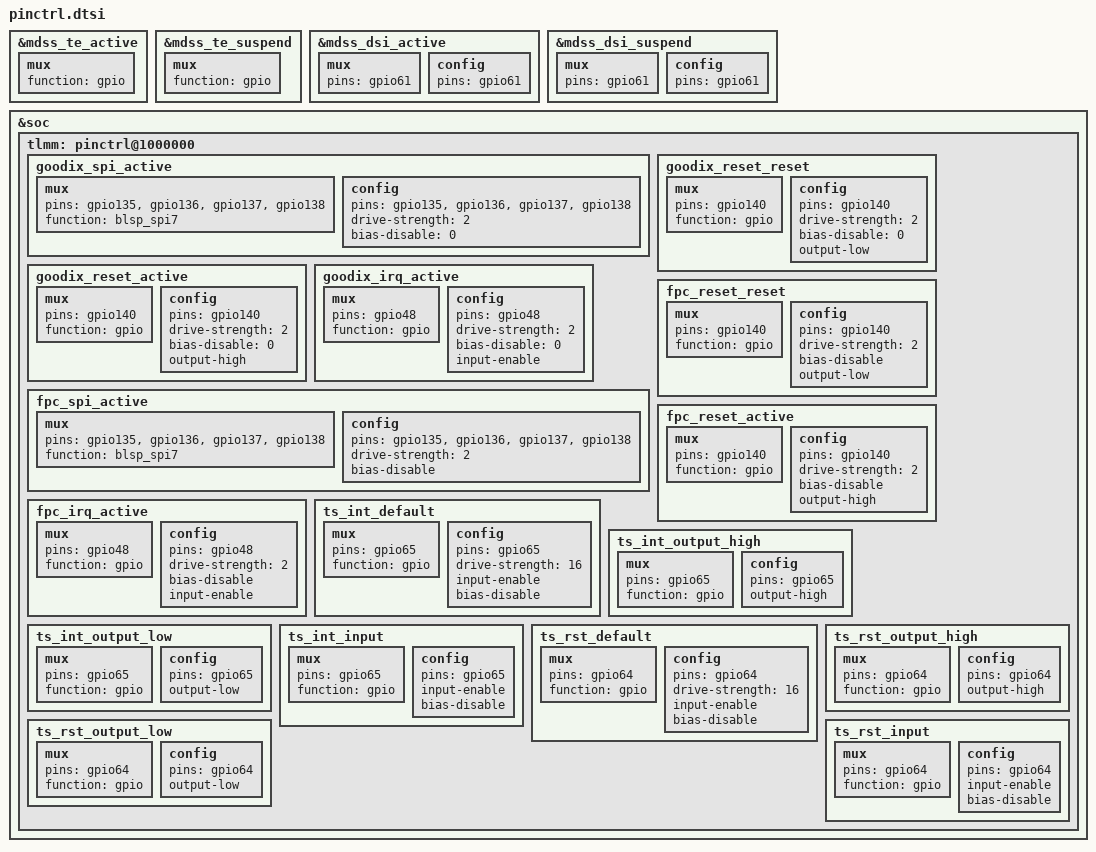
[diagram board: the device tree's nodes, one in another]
&mdss_te_active {
    mux {
        function = "gpio";
    };
};

&mdss_te_suspend {
    mux {
        function = "gpio";
    };
};

&mdss_dsi_active {
    mux {
        pins = "gpio61";
    };
    config {
        pins = "gpio61";
    };
};
&mdss_dsi_suspend {
    mux {
        pins = "gpio61";
    };
    config {
        pins = "gpio61";
    };
};

&soc {
	tlmm: pinctrl@1000000 {
		goodix_spi_active: goodix_spi_active{
			mux {
				pins = "gpio135", "gpio136", "gpio137", "gpio138";
				function = "blsp_spi7";
			};

			config {
				pins = "gpio135", "gpio136", "gpio137", "gpio138";
				drive-strength = <2>;
				bias-disable = <0>;
			};
		};

		goodix_reset_reset: goodix_reset_reset{
			mux {
				pins = "gpio140";
				function = "gpio";
			};

			config {
				pins = "gpio140";
				drive-strength = <2>;
				bias-disable = <0>;
				output-low;
			};
		};

		goodix_reset_active: goodix_reset_active{
			mux {
				pins = "gpio140";
				function = "gpio";
			};

			config {
				pins = "gpio140";
				drive-strength = <2>;
				bias-disable = <0>;
				output-high;
			};
		};

		goodix_irq_active: goodix_irq_active {
			mux {
				pins = "gpio48";
				function = "gpio";
			};

			config {
				pins = "gpio48";
				drive-strength = <2>;
				bias-disable = <0>;
				input-enable;
			};
		};

		/* fingerprint pin function */
		fpc_spi_active: fpc_spi_active {
			mux {
				pins = "gpio135", "gpio136", "gpio137", "gpio138";
				function = "blsp_spi7";
			};

			config {
				pins = "gpio135", "gpio136", "gpio137", "gpio138";
				drive-strength = <2>;
				bias-disable;
			};
		};

		fpc_reset_reset: fpc_reset_reset {
			mux {
				pins = "gpio140";
				function = "gpio";
			};

			config {
				pins = "gpio140";
				drive-strength = <2>;
				bias-disable;
				output-low;
			};
		};

		fpc_reset_active: fpc_reset_active {
			mux {
				pins = "gpio140";
				function = "gpio";
			};

			config {
				pins = "gpio140";
				drive-strength = <2>;
				bias-disable;
				output-high;
			};
		};

		fpc_irq_active: fpc_irq_active {
			mux {
				pins = "gpio48";
				function = "gpio";
			};

			config {
				pins = "gpio48";
				drive-strength = <2>;
				bias-disable;
				input-enable;
			};
		};
	};
};

/* Custom */
&tlmm {
	/* add pingrp for goodix touch */
	ts_int_default: ts_int_default {
		mux {
			pins = "gpio65";
			function = "gpio";
		};
		config {
			pins = "gpio65";
			drive-strength = <16>;
			/*bias-pull-up;*/
			input-enable;
			bias-disable;
		};
	};

	ts_int_output_high: ts_int_output_high {
		mux {
			pins = "gpio65";
			function = "gpio";
		};
		config {
			pins = "gpio65";
			output-high;
		};
	};

	ts_int_output_low: ts_int_output_low {
		mux {
			pins = "gpio65";
			function = "gpio";
		};
		config {
			pins = "gpio65";
			output-low;
		};
	};

	ts_int_input: ts_int_input {
		mux {
			pins = "gpio65";
			function = "gpio";
		};
		config {
			pins = "gpio65";
			input-enable;
			bias-disable;
		};
	};

	ts_rst_default: ts_rst_default {
		mux {
			pins = "gpio64";
			function = "gpio";
		};
		config {
			pins = "gpio64";
			drive-strength = <16>;
			/*bias-pull-up;*/
			input-enable;
			bias-disable;
		};
	};

	ts_rst_output_high: ts_rst_output_high {
		mux {
			pins = "gpio64";
			function = "gpio";
		};
		config {
			pins = "gpio64";
			output-high;
		};
	};

	ts_rst_output_low: ts_rst_output_low {
		mux {
			pins = "gpio64";
			function = "gpio";
		};
		config {
			pins = "gpio64";
			output-low;
		};
	};

	ts_rst_input: ts_rst_input {
		mux {
			pins = "gpio64";
			function = "gpio";
		};
		config {
			pins = "gpio64";
			input-enable;
			bias-disable;
		};
	};
};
